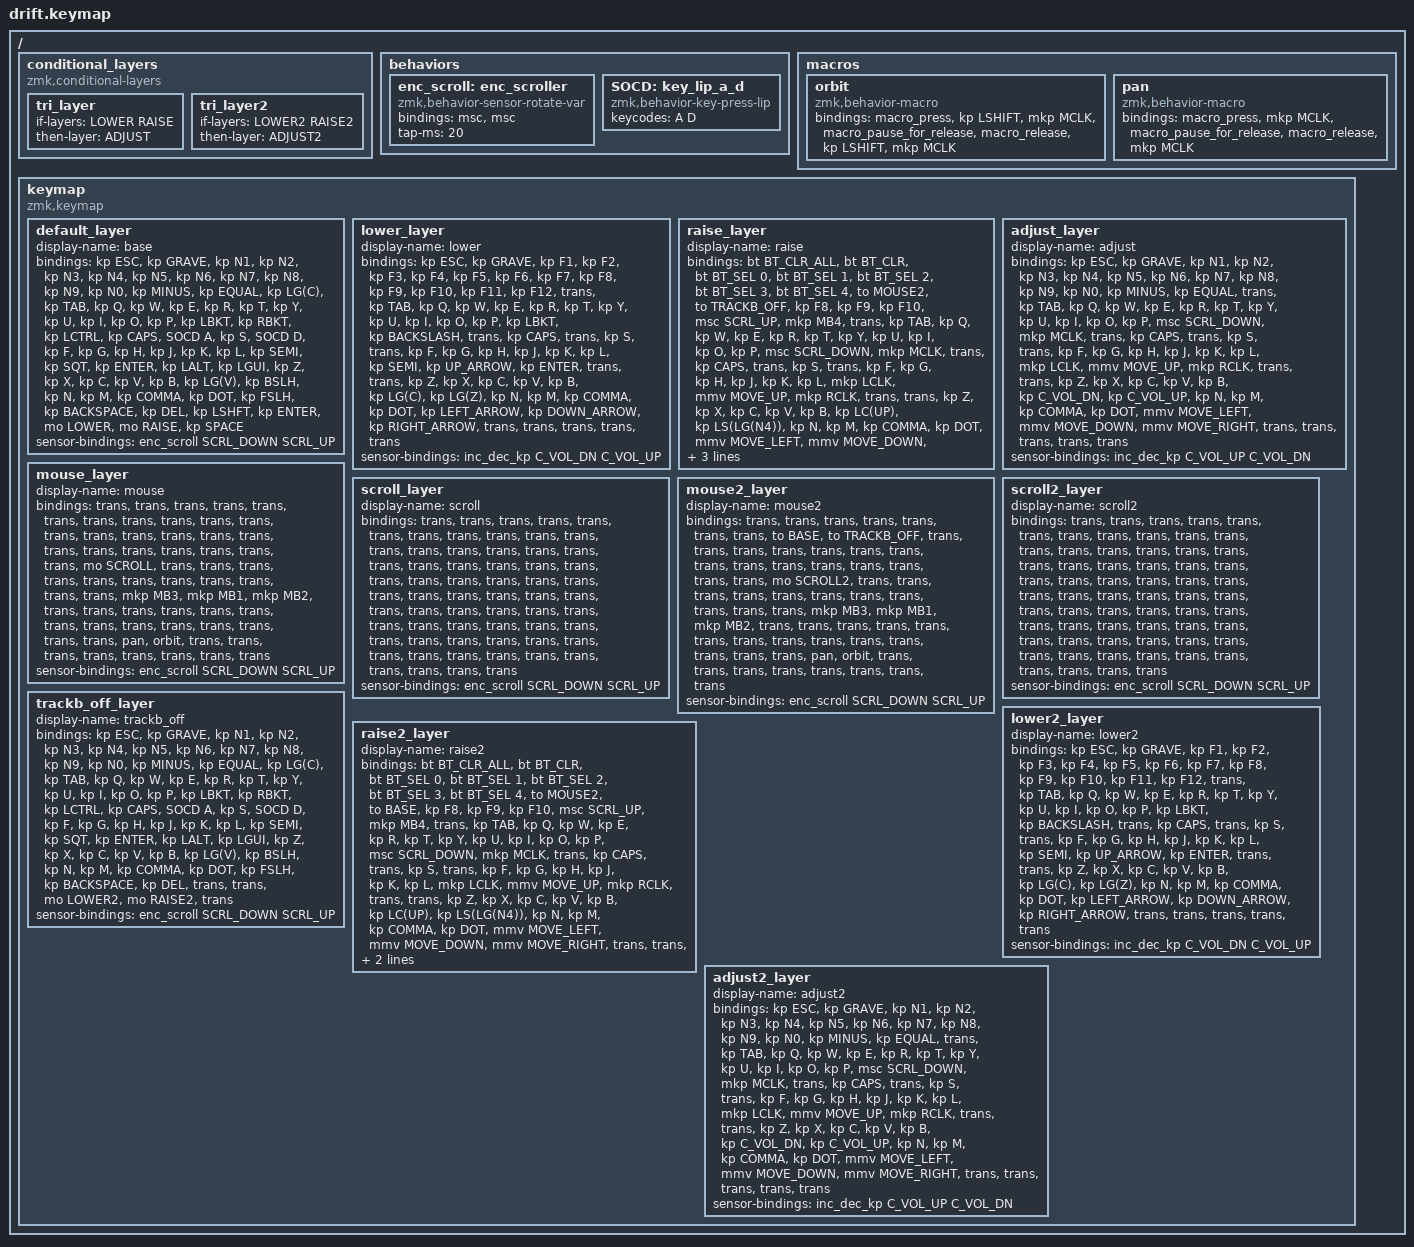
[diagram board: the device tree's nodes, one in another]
// Copyright (c) 2025 The ZMK Contributors
// SPDX-License-Identifier: MIT

// Default scroll sensitivity for encoder-based scrolling
#define ZMK_POINTING_DEFAULT_SCRL_VAL 100    // default was 10

#include <behaviors.dtsi>
#include <dt-bindings/zmk/bt.h>
#include <input/processors.dtsi>
#include <dt-bindings/zmk/keys.h>
#include <dt-bindings/zmk/mouse.h>
#include <behaviors/mouse_keys.dtsi>
#include <dt-bindings/zmk/pointing.h>
#include <dt-bindings/zmk/input_transform.h>
#include <zephyr/dt-bindings/input/input-event-codes.h>

// Keep all behavior settings visible in ZMK Studio
#define ZMK_BEHAVIORS_OMIT_KT

// Layer indices
#define BASE        0
#define LOWER       1
#define RAISE       2
#define ADJUST      3
#define MOUSE       4
#define SCROLL      5
#define MOUSE2      6
#define SCROLL2     7
#define TRACKB_OFF  8
#define LOWER2      9
#define RAISE2      10
#define ADJUST2     11

// Reference: https://zmk.dev/docs/keymaps/behaviors/

/ {
    conditional_layers {
        compatible = "zmk,conditional-layers";

        tri_layer {
            if-layers = <LOWER RAISE>;
            then-layer = <ADJUST>;
        };

        tri_layer2 {
            if-layers = <LOWER2 RAISE2>;
            then-layer = <ADJUST2>;
        };
    };

    behaviors {
        enc_scroll: enc_scroller {
            compatible = "zmk,behavior-sensor-rotate-var";
            #sensor-binding-cells = <2>;
            bindings = <&msc>, <&msc>;
            tap-ms = <20>;
        };
		
		/* Setup left and right */
        SOCD: key_lip_a_d {
                compatible = "zmk,behavior-key-press-lip";
                #binding-cells = <1>;
                keycodes = <A D>;
        };

    };

    macros {
        orbit: orbit {
            compatible = "zmk,behavior-macro";
            #binding-cells = <0>;
            bindings =
                <&macro_press &kp LSHIFT &mkp MCLK>,
                <&macro_pause_for_release>,
                <&macro_release &kp LSHIFT &mkp MCLK>;
        };

        pan: pan {
            compatible = "zmk,behavior-macro";
            #binding-cells = <0>;
            bindings =
                <&macro_press &mkp MCLK>,
                <&macro_pause_for_release>,
                <&macro_release &mkp MCLK>;
        };
    };

    keymap {
        compatible = "zmk,keymap";

        // -------------------------------------------------------------------------------
        // BASE Layer
        // -------------------------------------------------------------------------------
       
        default_layer {
            display-name = "base";
            bindings = <
                &kp ESC    &kp GRAVE &kp N1   &kp N2   &kp N3    &kp N4    &kp N5                       &kp N6    &kp N7    &kp N8    &kp N9  &kp N0   &kp MINUS     &kp EQUAL
                &kp LG(C)  &kp TAB   &kp Q    &kp W    &kp E     &kp R     &kp T                        &kp Y     &kp U     &kp I     &kp O   &kp P    &kp LBKT      &kp RBKT
                &kp LCTRL  &kp CAPS  &SOCD A  &kp S    &SOCD D   &kp F     &kp G                        &kp H     &kp J     &kp K     &kp L   &kp SEMI &kp SQT       &kp ENTER
                &kp LALT   &kp LGUI  &kp Z    &kp X    &kp C     &kp V     &kp B     &kp LG(V) &kp BSLH &kp N     &kp M     &kp COMMA &kp DOT &kp FSLH &kp BACKSPACE &kp DEL
                                                       &kp LSHFT &kp ENTER &mo LOWER                    &mo RAISE &kp SPACE
            >;
            sensor-bindings = <&enc_scroll SCRL_DOWN SCRL_UP>;
        };

        // ------------------------------------------------------------------------
        // LOWER Layer
        // ------------------------------------------------------------------------
		
        lower_layer {
            display-name = "lower";
            bindings = <
                &kp ESC   &kp GRAVE &kp F1 &kp F2 &kp F3  &kp F4  &kp F5                        &kp F6  &kp F7    &kp F8    &kp F9    &kp F10        &kp F11        &kp F12
                &trans    &kp TAB   &kp Q  &kp W  &kp E   &kp R   &kp T                         &kp Y   &kp U     &kp I     &kp O     &kp P          &kp LBKT       &kp BACKSLASH
                &trans    &kp CAPS  &trans &kp S  &trans  &kp F   &kp G                         &kp H   &kp J     &kp K     &kp L     &kp SEMI       &kp UP_ARROW   &kp ENTER
                &trans    &trans    &kp Z  &kp X  &kp C   &kp V   &kp B   &kp LG(C)  &kp LG(Z)  &kp N   &kp M     &kp COMMA &kp DOT   &kp LEFT_ARROW &kp DOWN_ARROW &kp RIGHT_ARROW
                                                  &trans  &trans  &trans                        &trans  &trans
            >;
            sensor-bindings = <&inc_dec_kp C_VOL_DN C_VOL_UP>;
        };

        // ---------------------------------------------------------------------------
        // RAISE Layer
        // ---------------------------------------------------------------------------
       
        raise_layer {
            display-name = "raise";
            bindings = <
                &bt BT_CLR_ALL &bt BT_CLR &bt BT_SEL 0 &bt BT_SEL 1 &bt BT_SEL 2 &bt BT_SEL 3  &bt BT_SEL 4                                &to MOUSE2 &to TRACKB_OFF  &kp F8    &kp F9  &kp F10        &msc SCRL_UP   &mkp MB4
                &trans         &kp TAB    &kp Q        &kp W        &kp E        &kp R         &kp T                                       &kp Y      &kp U           &kp I     &kp O   &kp P          &msc SCRL_DOWN &mkp MCLK
                &trans         &kp CAPS   &trans       &kp S        &trans       &kp F         &kp G                                       &kp H      &kp J           &kp K     &kp L   &mkp LCLK      &mmv MOVE_UP   &mkp RCLK
                &trans         &trans     &kp Z        &kp X        &kp C        &kp V         &kp B         &kp LC(UP)    &kp LS(LG(N4))  &kp N      &kp M           &kp COMMA &kp DOT &mmv MOVE_LEFT &mmv MOVE_DOWN &mmv MOVE_RIGHT
                                                                    &trans       &trans        &trans                                      &trans     &trans
            >;
            sensor-bindings = <&inc_dec_kp C_VOL_DN C_VOL_UP>;
        };

        // ---------------------------------------------------------------------
        // ADJUST Layer  (auto-activated when LOWER + RAISE are held simultaneously)
        // ---------------------------------------------------------------------
        
        adjust_layer {
            display-name = "adjust";
            bindings = <
                &kp ESC    &kp GRAVE  &kp N1       &kp N2       &kp N3   &kp N4    &kp N5                             &kp N6 &kp N7    &kp N8    &kp N9  &kp N0         &kp MINUS      &kp EQUAL
                &trans     &kp TAB    &kp Q        &kp W        &kp E    &kp R     &kp T                              &kp Y  &kp U     &kp I     &kp O   &kp P          &msc SCRL_DOWN &mkp MCLK
                &trans     &kp CAPS   &trans       &kp S        &trans   &kp F     &kp G                              &kp H  &kp J     &kp K     &kp L   &mkp LCLK      &mmv MOVE_UP   &mkp RCLK
                &trans     &trans     &kp Z        &kp X        &kp C    &kp V     &kp B   &kp C_VOL_DN &kp C_VOL_UP  &kp N  &kp M     &kp COMMA &kp DOT &mmv MOVE_LEFT &mmv MOVE_DOWN &mmv MOVE_RIGHT
                                                                &trans   &trans    &trans                             &trans &trans
            >;
            sensor-bindings = <&inc_dec_kp C_VOL_UP C_VOL_DN>;
        };

        // ---------------------------------------------------------------------
        // MOUSE Layer  (momentary, activated from BASE)
        // ---------------------------------------------------------------------
        
        mouse_layer {
            display-name = "mouse";
            bindings = <
                &trans &trans &trans &trans &trans &trans &trans               &trans &trans   &trans   &trans     &trans &trans &trans
                &trans &trans &trans &trans &trans &trans &trans               &trans &trans   &trans   &mo SCROLL &trans &trans &trans
                &trans &trans &trans &trans &trans &trans &trans               &trans &mkp MB3 &mkp MB1 &mkp MB2   &trans &trans &trans
                &trans &trans &trans &trans &trans &trans &trans &trans &trans &trans &trans   &pan     &orbit     &trans &trans &trans
                                            &trans &trans &trans               &trans &trans
            >;
            sensor-bindings = <&enc_scroll SCRL_DOWN SCRL_UP>;
        };

        // SCROLL / MOUSE2  layers remain mostly transparent and is used for when you want to turn mouse mode on indefinitely (activated on RAISE Layer - "&to MOUSE2")
        
        scroll_layer {
            display-name = "scroll";
            bindings = <
                &trans &trans &trans &trans &trans &trans &trans               &trans &trans &trans &trans &trans &trans &trans
                &trans &trans &trans &trans &trans &trans &trans               &trans &trans &trans &trans &trans &trans &trans
                &trans &trans &trans &trans &trans &trans &trans               &trans &trans &trans &trans &trans &trans &trans
                &trans &trans &trans &trans &trans &trans &trans &trans &trans &trans &trans &trans &trans &trans &trans &trans
                                            &trans &trans &trans               &trans &trans
            >;
            sensor-bindings = <&enc_scroll SCRL_DOWN SCRL_UP>;
        };

        // ---------------------------------------------------------------------
        // MOUSE2 Layer  (toggle, activated from RAISE - stays on until BASE is pressed)
        // ---------------------------------------------------------------------
        
       mouse2_layer {
            display-name = "mouse2";
            bindings = <
                &trans &trans &trans &trans &trans &trans &trans               &to BASE &to TRACKB_OFF  &trans   &trans      &trans &trans &trans
                &trans &trans &trans &trans &trans &trans &trans               &trans   &trans          &trans   &mo SCROLL2 &trans &trans &trans
                &trans &trans &trans &trans &trans &trans &trans               &trans   &mkp MB3        &mkp MB1 &mkp MB2    &trans &trans &trans
                &trans &trans &trans &trans &trans &trans &trans &trans &trans &trans   &trans          &pan     &orbit      &trans &trans &trans
                                            &trans &trans &trans               &trans   &trans
            >;
            sensor-bindings = <&enc_scroll SCRL_DOWN SCRL_UP>;
        };
		
        // ---------------------------------------------------------------------
        // SCROLL2 Layer  (momentary, activated from MOUSE2 layer - all keys transparent)
        // ---------------------------------------------------------------------
		
        scroll2_layer {
            display-name = "scroll2";
            bindings = <
                &trans &trans &trans &trans &trans &trans &trans               &trans &trans &trans &trans &trans &trans &trans
                &trans &trans &trans &trans &trans &trans &trans               &trans &trans &trans &trans &trans &trans &trans
                &trans &trans &trans &trans &trans &trans &trans               &trans &trans &trans &trans &trans &trans &trans
                &trans &trans &trans &trans &trans &trans &trans &trans &trans &trans &trans &trans &trans &trans &trans &trans
                                            &trans &trans &trans               &trans &trans
            >;
            sensor-bindings = <&enc_scroll SCRL_DOWN SCRL_UP>;
        };

        trackb_off_layer {
            display-name = "trackb_off";
            bindings = <
                &kp ESC    &kp GRAVE &kp N1   &kp N2   &kp N3    &kp N4    &kp N5                        &kp N6     &kp N7    &kp N8    &kp N9  &kp N0   &kp MINUS     &kp EQUAL
                &kp LG(C)  &kp TAB   &kp Q    &kp W    &kp E     &kp R     &kp T                         &kp Y      &kp U     &kp I     &kp O   &kp P    &kp LBKT      &kp RBKT
                &kp LCTRL  &kp CAPS  &SOCD A  &kp S    &SOCD D   &kp F     &kp G                         &kp H      &kp J     &kp K     &kp L   &kp SEMI &kp SQT       &kp ENTER
                &kp LALT   &kp LGUI  &kp Z    &kp X    &kp C     &kp V     &kp B      &kp LG(V) &kp BSLH &kp N      &kp M     &kp COMMA &kp DOT &kp FSLH &kp BACKSPACE &kp DEL
                                                       &trans    &trans    &mo LOWER2                    &mo RAISE2 &trans
            >;
            sensor-bindings = <&enc_scroll SCRL_DOWN SCRL_UP>;
        };
		
        lower2_layer {
            display-name = "lower2";
            bindings = <
                &kp ESC   &kp GRAVE &kp F1 &kp F2 &kp F3  &kp F4  &kp F5                         &kp F6  &kp F7    &kp F8    &kp F9    &kp F10        &kp F11        &kp F12
                &trans    &kp TAB   &kp Q  &kp W  &kp E   &kp R   &kp T                          &kp Y   &kp U     &kp I     &kp O     &kp P          &kp LBKT       &kp BACKSLASH
                &trans    &kp CAPS  &trans &kp S  &trans  &kp F   &kp G                          &kp H   &kp J     &kp K     &kp L     &kp SEMI       &kp UP_ARROW   &kp ENTER
                &trans    &trans    &kp Z  &kp X  &kp C   &kp V   &kp B   &kp LG(C)   &kp LG(Z)  &kp N   &kp M     &kp COMMA &kp DOT   &kp LEFT_ARROW &kp DOWN_ARROW &kp RIGHT_ARROW
                                                  &trans  &trans  &trans                         &trans  &trans
            >;
            sensor-bindings = <&inc_dec_kp C_VOL_DN C_VOL_UP>;
        };

        raise2_layer {
            display-name = "raise2";
            bindings = <
                &bt BT_CLR_ALL &bt BT_CLR &bt BT_SEL 0 &bt BT_SEL 1 &bt BT_SEL 2 &bt BT_SEL 3  &bt BT_SEL 4                                &to MOUSE2 &to BASE  &kp F8    &kp F9  &kp F10        &msc SCRL_UP   &mkp MB4
                &trans         &kp TAB    &kp Q        &kp W        &kp E        &kp R         &kp T                                       &kp Y      &kp U     &kp I     &kp O   &kp P          &msc SCRL_DOWN &mkp MCLK
                &trans         &kp CAPS   &trans       &kp S        &trans       &kp F         &kp G                                       &kp H      &kp J     &kp K     &kp L   &mkp LCLK      &mmv MOVE_UP   &mkp RCLK
                &trans         &trans     &kp Z        &kp X        &kp C        &kp V         &kp B         &kp LC(UP)    &kp LS(LG(N4))  &kp N      &kp M     &kp COMMA &kp DOT &mmv MOVE_LEFT &mmv MOVE_DOWN &mmv MOVE_RIGHT
                                                                    &trans       &trans        &trans                                      &trans     &trans
            >;
            sensor-bindings = <&inc_dec_kp C_VOL_DN C_VOL_UP>;
        };

        adjust2_layer {
            display-name = "adjust2";
            bindings = <
                &kp ESC    &kp GRAVE  &kp N1       &kp N2       &kp N3       &kp N4       &kp N5                             &kp N6  &kp N7  &kp N8    &kp N9  &kp N0         &kp MINUS      &kp EQUAL
                &trans     &kp TAB    &kp Q        &kp W        &kp E        &kp R        &kp T                              &kp Y   &kp U   &kp I     &kp O   &kp P          &msc SCRL_DOWN &mkp MCLK
                &trans     &kp CAPS   &trans       &kp S        &trans       &kp F        &kp G                              &kp H   &kp J   &kp K     &kp L   &mkp LCLK      &mmv MOVE_UP   &mkp RCLK
                &trans     &trans     &kp Z        &kp X        &kp C        &kp V        &kp B    &kp C_VOL_DN &kp C_VOL_UP &kp N   &kp M   &kp COMMA &kp DOT &mmv MOVE_LEFT &mmv MOVE_DOWN &mmv MOVE_RIGHT
                                                                &trans       &trans       &trans                             &trans  &trans
            >;
            sensor-bindings = <&inc_dec_kp C_VOL_UP C_VOL_DN>;
        };
    };
};
